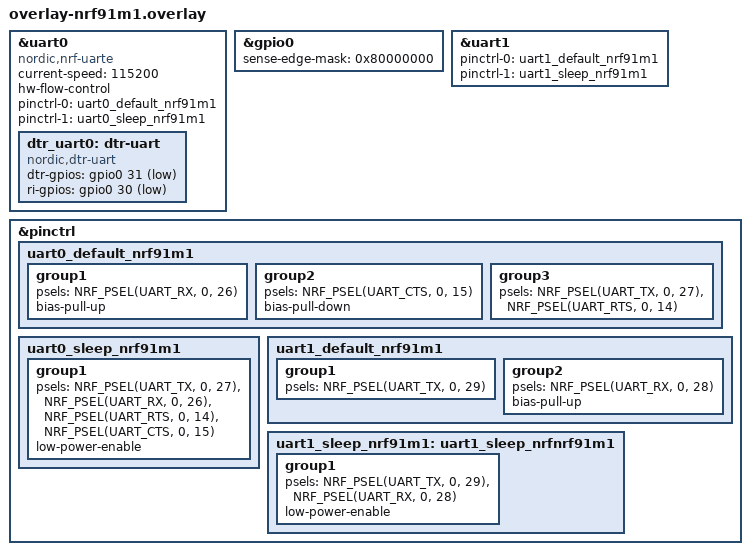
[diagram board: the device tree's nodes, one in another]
/*
 * Copyright (c) 2026 Nordic Semiconductor ASA
 *
 * SPDX-License-Identifier: LicenseRef-Nordic-5-Clause
 */

/* AT command UART */
&uart0 {
	compatible = "nordic,nrf-uarte";
	current-speed = <115200>;
	hw-flow-control;
	status = "okay";

	dtr_uart0: dtr-uart {
		compatible = "nordic,dtr-uart";
		dtr-gpios = <&gpio0 31 (GPIO_PULL_UP | GPIO_ACTIVE_LOW)>; /* 9151 SiP LGA pin: 50 */
		ri-gpios = <&gpio0 30 GPIO_ACTIVE_LOW>; /* 9151 SiP LGA pin: 49 */
		status = "okay";
	};
	pinctrl-0 = <&uart0_default_nrf91m1>;
	pinctrl-1 = <&uart0_sleep_nrf91m1>;
	pinctrl-names = "default", "sleep";
};

&gpio0 {
	status = "okay";
	/* Use PORT event for DTR (31) pin to save power */
	sense-edge-mask = <0x80000000>;
};

/* Log / Trace UART */
&uart1 {
	pinctrl-0 = <&uart1_default_nrf91m1>;
	pinctrl-1 = <&uart1_sleep_nrf91m1>;
	pinctrl-names = "default", "sleep";
};

&pinctrl {
	uart0_default_nrf91m1: uart0_default_nrf91m1 {
		group1 {
			psels = <NRF_PSEL(UART_RX, 0, 26)>; /* 9151 SiP LGA pin: 44 */
			bias-pull-up;
		};
		group2 {
			psels = <NRF_PSEL(UART_CTS, 0, 15)>; /* 9151 SiP LGA pin: 75 */
			bias-pull-down;
		};
		group3 {
			psels = <NRF_PSEL(UART_TX, 0, 27)>, /* 9151 SiP LGA pin: 45 */
				<NRF_PSEL(UART_RTS, 0, 14)>; /* 9151 SiP LGA pin: 74 */
		};
	};

	uart0_sleep_nrf91m1: uart0_sleep_nrf91m1 {
		group1 {
			psels = <NRF_PSEL(UART_TX, 0, 27)>,
				<NRF_PSEL(UART_RX, 0, 26)>,
				<NRF_PSEL(UART_RTS, 0, 14)>,
				<NRF_PSEL(UART_CTS, 0, 15)>;
			low-power-enable;
		};
	};

	uart1_default_nrf91m1: uart1_default_nrf91m1 {
		group1 {
			psels = <NRF_PSEL(UART_TX, 0, 29)>; /* 9151 SiP LGA pin: 48 */
		};

		group2 {
			psels = <NRF_PSEL(UART_RX, 0, 28)>; /* 9151 SiP LGA pin: 47 (floating) */
			bias-pull-up;
		};
	};

	uart1_sleep_nrf91m1: uart1_sleep_nrfnrf91m1 {
		group1 {
			psels = <NRF_PSEL(UART_TX, 0, 29)>,
				<NRF_PSEL(UART_RX, 0, 28)>;
			low-power-enable;
		};
	};
};
